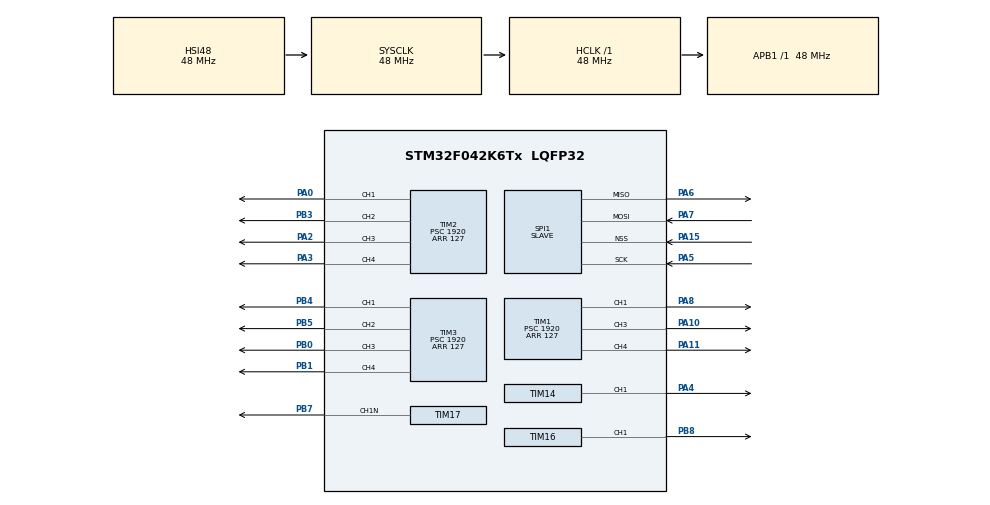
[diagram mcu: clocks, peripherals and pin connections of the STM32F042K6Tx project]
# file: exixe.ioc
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Dma.Request0=SPI1_RX
Dma.SPI1_RX.0.Direction=DMA_PERIPH_TO_MEMORY
Dma.SPI1_RX.0.Instance=DMA1_Channel2
Dma.SPI1_RX.0.MemDataAlignment=DMA_MDATAALIGN_BYTE
Dma.SPI1_RX.0.MemInc=DMA_MINC_ENABLE
Dma.SPI1_RX.0.Mode=DMA_NORMAL
Dma.SPI1_RX.0.PeriphDataAlignment=DMA_PDATAALIGN_BYTE
Dma.SPI1_RX.0.PeriphInc=DMA_PINC_DISABLE
Dma.SPI1_RX.0.Priority=DMA_PRIORITY_HIGH
IWDG.Prescaler=IWDG_PRESCALER_4
Mcu.Family=STM32F0
Mcu.Name=STM32F042K6Tx
Mcu.Package=LQFP32
NVIC.DMA1_Channel2_3_IRQn=true\:0\:0\:false\:false\:true\:true
PA0.Signal=S_TIM2_CH1_ETR
PA10.Signal=S_TIM1_CH3
PA11.Signal=S_TIM1_CH4
PA13.Mode=Serial_Wire
PA13.Signal=SYS_SWDIO
PA14.Mode=Serial_Wire
PA14.Signal=SYS_SWCLK
PA15.Mode=NSS_Signal_Hard_Input
PA15.Signal=SPI1_NSS
PA2.Signal=S_TIM2_CH3
PA3.Signal=S_TIM2_CH4
PA4.Signal=S_TIM14_CH1
PA5.Mode=Full_Duplex_Slave
PA5.Signal=SPI1_SCK
PA6.Mode=Full_Duplex_Slave
PA6.Signal=SPI1_MISO
PA7.Mode=Full_Duplex_Slave
PA7.Signal=SPI1_MOSI
PA8.Signal=S_TIM1_CH1
PB0.Signal=S_TIM3_CH3
PB1.Signal=S_TIM3_CH4
PB3.Signal=S_TIM2_CH2
PB4.Signal=S_TIM3_CH1
PB5.Signal=S_TIM3_CH2
PB7.Mode=PWM Generation1 CH1N
PB7.Signal=TIM17_CH1N
PB8.Signal=S_TIM16_CH1
ProjectManager.HeapSize=0x200
ProjectManager.StackSize=0x400
ProjectManager.TargetToolchain=MDK-ARM V5
RCC.AHBFreq_Value=48000000
RCC.APB1Freq_Value=48000000
RCC.APB1TimFreq_Value=48000000
RCC.HCLKFreq_Value=48000000
RCC.I2c1ClockSelection=RCC_I2C1CLKSOURCE_SYSCLK
RCC.SYSCLKFreq_VALUE=48000000
RCC.SYSCLKSource=RCC_SYSCLKSOURCE_HSI48
RCC.Usart1ClockSelection=RCC_USART1CLKSOURCE_SYSCLK
SH.S_TIM14_CH1.0=TIM14_CH1,PWM Generation1 CH1
SH.S_TIM16_CH1.0=TIM16_CH1,PWM Generation1 CH1
SH.S_TIM1_CH1.0=TIM1_CH1,PWM Generation1 CH1
SH.S_TIM1_CH3.0=TIM1_CH3,PWM Generation3 CH3
SH.S_TIM1_CH4.0=TIM1_CH4,PWM Generation4 CH4
SH.S_TIM2_CH1_ETR.0=TIM2_CH1,PWM Generation1 CH1
SH.S_TIM2_CH2.0=TIM2_CH2,PWM Generation2 CH2
SH.S_TIM2_CH3.0=TIM2_CH3,PWM Generation3 CH3
SH.S_TIM2_CH4.0=TIM2_CH4,PWM Generation4 CH4
SH.S_TIM3_CH1.0=TIM3_CH1,PWM Generation1 CH1
SH.S_TIM3_CH2.0=TIM3_CH2,PWM Generation2 CH2
SH.S_TIM3_CH3.0=TIM3_CH3,PWM Generation3 CH3
SH.S_TIM3_CH4.0=TIM3_CH4,PWM Generation4 CH4
SPI1.DataSize=SPI_DATASIZE_8BIT
SPI1.Direction=SPI_DIRECTION_2LINES
SPI1.Mode=SPI_MODE_SLAVE
SPI1.VirtualNSS=VM_NSSHARD
SPI1.VirtualType=VM_SLAVE
TIM1.Channel-PWM\ Generation1\ CH1=TIM_CHANNEL_1
TIM1.Channel-PWM\ Generation3\ CH3=TIM_CHANNEL_3
TIM1.Channel-PWM\ Generation4\ CH4=TIM_CHANNEL_4
TIM1.Period=127
TIM1.Prescaler=1920
TIM1.Pulse-PWM\ Generation1\ CH1=0
TIM1.Pulse-PWM\ Generation4\ CH4=0
TIM14.Channel=TIM_CHANNEL_1
TIM14.Period=127
TIM14.Prescaler=1920
TIM14.Pulse=0
TIM16.Channel=TIM_CHANNEL_1
TIM16.Period=127
TIM16.Prescaler=1920
TIM17.Channel=TIM_CHANNEL_1
TIM17.Period=127
TIM17.Prescaler=1920
TIM17.Pulse=0
TIM2.Channel-PWM\ Generation1\ CH1=TIM_CHANNEL_1
TIM2.Channel-PWM\ Generation2\ CH2=TIM_CHANNEL_2
TIM2.Channel-PWM\ Generation3\ CH3=TIM_CHANNEL_3
TIM2.Channel-PWM\ Generation4\ CH4=TIM_CHANNEL_4
TIM2.Period=127
TIM2.Prescaler=1920
TIM2.Pulse-PWM\ Generation1\ CH1=0
TIM2.Pulse-PWM\ Generation2\ CH2=0
TIM2.Pulse-PWM\ Generation3\ CH3=0
TIM2.Pulse-PWM\ Generation4\ CH4=0
TIM3.Channel-PWM\ Generation1\ CH1=TIM_CHANNEL_1
TIM3.Channel-PWM\ Generation2\ CH2=TIM_CHANNEL_2
TIM3.Channel-PWM\ Generation3\ CH3=TIM_CHANNEL_3
TIM3.Channel-PWM\ Generation4\ CH4=TIM_CHANNEL_4
TIM3.Period=127
TIM3.Prescaler=1920
TIM3.Pulse-PWM\ Generation1\ CH1=0
TIM3.Pulse-PWM\ Generation2\ CH2=0
TIM3.Pulse-PWM\ Generation3\ CH3=0
TIM3.Pulse-PWM\ Generation4\ CH4=0
VP_IWDG_VS_IWDG.Mode=IWDG_Activate
VP_TIM14_VS_ClockSourceINT.Mode=Enable_Timer
VP_TIM16_VS_ClockSourceINT.Mode=Enable_Timer
VP_TIM17_VS_ClockSourceINT.Mode=Enable_Timer
VP_TIM1_VS_ClockSourceINT.Mode=Internal
VP_TIM2_VS_ClockSourceINT.Mode=Internal
VP_TIM3_VS_ClockSourceINT.Mode=Internal
board=exixe

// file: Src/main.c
/**
  ******************************************************************************
  * File Name          : main.c
  * Description        : Main program body
  ******************************************************************************
  ** This notice applies to any and all portions of this file
  * that are not between comment pairs USER CODE BEGIN and
  * USER CODE END. Other portions of this file, whether
  * inserted by the user or by software development tools
  * are owned by their respective copyright owners.
  *
  * COPYRIGHT(c) 2017 STMicroelectronics
  *
  * Redistribution and use in source and binary forms, with or without modification,
  * are permitted provided that the following conditions are met:
  *   1. Redistributions of source code must retain the above copyright notice,
  *      this list of conditions and the following disclaimer.
  *   2. Redistributions in binary form must reproduce the above copyright notice,
  *      this list of conditions and the following disclaimer in the documentation
  *      and/or other materials provided with the distribution.
  *   3. Neither the name of STMicroelectronics nor the names of its contributors
  *      may be used to endorse or promote products derived from this software
  *      without specific prior written permission.
  *
  * THIS SOFTWARE IS PROVIDED BY THE COPYRIGHT HOLDERS AND CONTRIBUTORS "AS IS"
  * AND ANY EXPRESS OR IMPLIED WARRANTIES, INCLUDING, BUT NOT LIMITED TO, THE
  * IMPLIED WARRANTIES OF MERCHANTABILITY AND FITNESS FOR A PARTICULAR PURPOSE ARE
  * DISCLAIMED. IN NO EVENT SHALL THE COPYRIGHT HOLDER OR CONTRIBUTORS BE LIABLE
  * FOR ANY DIRECT, INDIRECT, INCIDENTAL, SPECIAL, EXEMPLARY, OR CONSEQUENTIAL
  * DAMAGES (INCLUDING, BUT NOT LIMITED TO, PROCUREMENT OF SUBSTITUTE GOODS OR
  * SERVICES; LOSS OF USE, DATA, OR PROFITS; OR BUSINESS INTERRUPTION) HOWEVER
  * CAUSED AND ON ANY THEORY OF LIABILITY, WHETHER IN CONTRACT, STRICT LIABILITY,
  * OR TORT (INCLUDING NEGLIGENCE OR OTHERWISE) ARISING IN ANY WAY OUT OF THE USE
  * OF THIS SOFTWARE, EVEN IF ADVISED OF THE POSSIBILITY OF SUCH DAMAGE.
  *
  ******************************************************************************
  */
#include "main.h"
#include "stm32f0xx_hal.h"

/* USER CODE BEGIN Includes */
#include "shared.h"
#include "helpers.h"

/* USER CODE END Includes */

IWDG_HandleTypeDef hiwdg;

SPI_HandleTypeDef hspi1;
DMA_HandleTypeDef hdma_spi1_rx;

TIM_HandleTypeDef htim1;
TIM_HandleTypeDef htim2;
TIM_HandleTypeDef htim3;
TIM_HandleTypeDef htim14;
TIM_HandleTypeDef htim16;
TIM_HandleTypeDef htim17;

/* USER CODE BEGIN PV */
/* Private variables ---------------------------------------------------------*/

/* USER CODE END PV */

void SystemClock_Config(void);
static void MX_GPIO_Init(void);
static void MX_DMA_Init(void);
static void MX_SPI1_Init(void);
static void MX_TIM14_Init(void);
static void MX_TIM3_Init(void);
static void MX_TIM16_Init(void);
static void MX_TIM1_Init(void);
static void MX_TIM2_Init(void);
static void MX_TIM17_Init(void);
static void MX_IWDG_Init(void);

void HAL_TIM_MspPostInit(TIM_HandleTypeDef *htim);

/* USER CODE BEGIN PFP */
/* Private function prototypes -----------------------------------------------*/
/* USER CODE END PFP */

int main(void)
{

  /* MCU Configuration----------------------------------------------------------*/

  /* Reset of all peripherals, Initializes the Flash interface and the Systick. */
  HAL_Init();

  /* Configure the system clock */
  SystemClock_Config();

  /* Initialize all configured peripherals */
  MX_GPIO_Init();
  MX_DMA_Init();
  MX_SPI1_Init();
  MX_TIM14_Init();
  MX_TIM3_Init();
  MX_TIM16_Init();
  MX_TIM1_Init();
  MX_TIM2_Init();
  MX_TIM17_Init();
  MX_IWDG_Init();

  /* Infinite loop */
  /* USER CODE BEGIN WHILE */
  timer_init();
  HAL_Delay(10);
  while (1)
  {
    HAL_IWDG_Refresh(&hiwdg);
    if(HAL_GPIO_ReadPin(GPIOA, GPIO_PIN_15) == GPIO_PIN_SET)
      HAL_SPI_Receive_DMA(&hspi1, spi_recv_buf, SPI_BUF_SIZE);
  /* USER CODE END WHILE */

  }

}

/** System Clock Configuration
*/
void SystemClock_Config(void)
{

  RCC_OscInitTypeDef RCC_OscInitStruct;
  RCC_ClkInitTypeDef RCC_ClkInitStruct;

    /**Initializes the CPU, AHB and APB busses clocks
    */
  RCC_OscInitStruct.OscillatorType = RCC_OSCILLATORTYPE_HSI48|RCC_OSCILLATORTYPE_LSI;
  RCC_OscInitStruct.HSI48State = RCC_HSI48_ON;
  RCC_OscInitStruct.LSIState = RCC_LSI_ON;
  RCC_OscInitStruct.PLL.PLLState = RCC_PLL_NONE;
  if (HAL_RCC_OscConfig(&RCC_OscInitStruct) != HAL_OK)
  {
    _Error_Handler(__FILE__, __LINE__);
  }

    /**Initializes the CPU, AHB and APB busses clocks
    */
  RCC_ClkInitStruct.ClockType = RCC_CLOCKTYPE_HCLK|RCC_CLOCKTYPE_SYSCLK
                              |RCC_CLOCKTYPE_PCLK1;
  RCC_ClkInitStruct.SYSCLKSource = RCC_SYSCLKSOURCE_HSI48;
  RCC_ClkInitStruct.AHBCLKDivider = RCC_SYSCLK_DIV1;
  RCC_ClkInitStruct.APB1CLKDivider = RCC_HCLK_DIV1;

  if (HAL_RCC_ClockConfig(&RCC_ClkInitStruct, FLASH_LATENCY_1) != HAL_OK)
  {
    _Error_Handler(__FILE__, __LINE__);
  }

    /**Configure the Systick interrupt time
    */
  HAL_SYSTICK_Config(HAL_RCC_GetHCLKFreq()/1000);

    /**Configure the Systick
    */
  HAL_SYSTICK_CLKSourceConfig(SYSTICK_CLKSOURCE_HCLK);

  /* SysTick_IRQn interrupt configuration */
  HAL_NVIC_SetPriority(SysTick_IRQn, 0, 0);
}

/* IWDG init function */
static void MX_IWDG_Init(void)
{

  hiwdg.Instance = IWDG;
  hiwdg.Init.Prescaler = IWDG_PRESCALER_4;
  hiwdg.Init.Window = 4095;
  hiwdg.Init.Reload = 4095;
  if (HAL_IWDG_Init(&hiwdg) != HAL_OK)
  {
    _Error_Handler(__FILE__, __LINE__);
  }

}

/* SPI1 init function */
static void MX_SPI1_Init(void)
{

  hspi1.Instance = SPI1;
  hspi1.Init.Mode = SPI_MODE_SLAVE;
  hspi1.Init.Direction = SPI_DIRECTION_2LINES;
  hspi1.Init.DataSize = SPI_DATASIZE_8BIT;
  hspi1.Init.CLKPolarity = SPI_POLARITY_LOW;
  hspi1.Init.CLKPhase = SPI_PHASE_1EDGE;
  hspi1.Init.NSS = SPI_NSS_HARD_INPUT;
  hspi1.Init.FirstBit = SPI_FIRSTBIT_MSB;
  hspi1.Init.TIMode = SPI_TIMODE_DISABLE;
  hspi1.Init.CRCCalculation = SPI_CRCCALCULATION_DISABLE;
  hspi1.Init.CRCPolynomial = 7;
  hspi1.Init.CRCLength = SPI_CRC_LENGTH_DATASIZE;
  hspi1.Init.NSSPMode = SPI_NSS_PULSE_DISABLE;
  if (HAL_SPI_Init(&hspi1) != HAL_OK)
  {
    _Error_Handler(__FILE__, __LINE__);
  }

}

/* TIM1 init function */
static void MX_TIM1_Init(void)
{

  TIM_ClockConfigTypeDef sClockSourceConfig;
  TIM_MasterConfigTypeDef sMasterConfig;
  TIM_OC_InitTypeDef sConfigOC;
  TIM_BreakDeadTimeConfigTypeDef sBreakDeadTimeConfig;

  htim1.Instance = TIM1;
  htim1.Init.Prescaler = 1920;
  htim1.Init.CounterMode = TIM_COUNTERMODE_UP;
  htim1.Init.Period = 127;
  htim1.Init.ClockDivision = TIM_CLOCKDIVISION_DIV1;
  htim1.Init.RepetitionCounter = 0;
  htim1.Init.AutoReloadPreload = TIM_AUTORELOAD_PRELOAD_DISABLE;
  if (HAL_TIM_Base_Init(&htim1) != HAL_OK)
  {
    _Error_Handler(__FILE__, __LINE__);
  }

  sClockSourceConfig.ClockSource = TIM_CLOCKSOURCE_INTERNAL;
  if (HAL_TIM_ConfigClockSource(&htim1, &sClockSourceConfig) != HAL_OK)
  {
    _Error_Handler(__FILE__, __LINE__);
  }

  if (HAL_TIM_PWM_Init(&htim1) != HAL_OK)
  {
    _Error_Handler(__FILE__, __LINE__);
  }

  sMasterConfig.MasterOutputTrigger = TIM_TRGO_RESET;
  sMasterConfig.MasterSlaveMode = TIM_MASTERSLAVEMODE_DISABLE;
  if (HAL_TIMEx_MasterConfigSynchronization(&htim1, &sMasterConfig) != HAL_OK)
  {
    _Error_Handler(__FILE__, __LINE__);
  }

  sConfigOC.OCMode = TIM_OCMODE_PWM1;
  sConfigOC.Pulse = 0;
  sConfigOC.OCPolarity = TIM_OCPOLARITY_HIGH;
  sConfigOC.OCNPolarity = TIM_OCNPOLARITY_HIGH;
  sConfigOC.OCFastMode = TIM_OCFAST_DISABLE;
  sConfigOC.OCIdleState = TIM_OCIDLESTATE_RESET;
  sConfigOC.OCNIdleState = TIM_OCNIDLESTATE_RESET;
  if (HAL_TIM_PWM_ConfigChannel(&htim1, &sConfigOC, TIM_CHANNEL_1) != HAL_OK)
  {
    _Error_Handler(__FILE__, __LINE__);
  }

  if (HAL_TIM_PWM_ConfigChannel(&htim1, &sConfigOC, TIM_CHANNEL_3) != HAL_OK)
  {
    _Error_Handler(__FILE__, __LINE__);
  }

  if (HAL_TIM_PWM_ConfigChannel(&htim1, &sConfigOC, TIM_CHANNEL_4) != HAL_OK)
  {
    _Error_Handler(__FILE__, __LINE__);
  }

  sBreakDeadTimeConfig.OffStateRunMode = TIM_OSSR_DISABLE;
  sBreakDeadTimeConfig.OffStateIDLEMode = TIM_OSSI_DISABLE;
  sBreakDeadTimeConfig.LockLevel = TIM_LOCKLEVEL_OFF;
  sBreakDeadTimeConfig.DeadTime = 0;
  sBreakDeadTimeConfig.BreakState = TIM_BREAK_DISABLE;
  sBreakDeadTimeConfig.BreakPolarity = TIM_BREAKPOLARITY_HIGH;
  sBreakDeadTimeConfig.AutomaticOutput = TIM_AUTOMATICOUTPUT_DISABLE;
  if (HAL_TIMEx_ConfigBreakDeadTime(&htim1, &sBreakDeadTimeConfig) != HAL_OK)
  {
    _Error_Handler(__FILE__, __LINE__);
  }

  HAL_TIM_MspPostInit(&htim1);

}

/* TIM2 init function */
static void MX_TIM2_Init(void)
{

  TIM_ClockConfigTypeDef sClockSourceConfig;
  TIM_MasterConfigTypeDef sMasterConfig;
  TIM_OC_InitTypeDef sConfigOC;

  htim2.Instance = TIM2;
  htim2.Init.Prescaler = 1920;
  htim2.Init.CounterMode = TIM_COUNTERMODE_UP;
  htim2.Init.Period = 127;
  htim2.Init.ClockDivision = TIM_CLOCKDIVISION_DIV1;
  htim2.Init.AutoReloadPreload = TIM_AUTORELOAD_PRELOAD_DISABLE;
  if (HAL_TIM_Base_Init(&htim2) != HAL_OK)
  {
    _Error_Handler(__FILE__, __LINE__);
  }

  sClockSourceConfig.ClockSource = TIM_CLOCKSOURCE_INTERNAL;
  if (HAL_TIM_ConfigClockSource(&htim2, &sClockSourceConfig) != HAL_OK)
  {
    _Error_Handler(__FILE__, __LINE__);
  }

  if (HAL_TIM_PWM_Init(&htim2) != HAL_OK)
  {
    _Error_Handler(__FILE__, __LINE__);
  }

  sMasterConfig.MasterOutputTrigger = TIM_TRGO_RESET;
  sMasterConfig.MasterSlaveMode = TIM_MASTERSLAVEMODE_DISABLE;
  if (HAL_TIMEx_MasterConfigSynchronization(&htim2, &sMasterConfig) != HAL_OK)
  {
    _Error_Handler(__FILE__, __LINE__);
  }

  sConfigOC.OCMode = TIM_OCMODE_PWM1;
  sConfigOC.Pulse = 0;
  sConfigOC.OCPolarity = TIM_OCPOLARITY_HIGH;
  sConfigOC.OCFastMode = TIM_OCFAST_DISABLE;
  if (HAL_TIM_PWM_ConfigChannel(&htim2, &sConfigOC, TIM_CHANNEL_1) != HAL_OK)
  {
    _Error_Handler(__FILE__, __LINE__);
  }

  if (HAL_TIM_PWM_ConfigChannel(&htim2, &sConfigOC, TIM_CHANNEL_2) != HAL_OK)
  {
    _Error_Handler(__FILE__, __LINE__);
  }

  if (HAL_TIM_PWM_ConfigChannel(&htim2, &sConfigOC, TIM_CHANNEL_3) != HAL_OK)
  {
    _Error_Handler(__FILE__, __LINE__);
  }

  if (HAL_TIM_PWM_ConfigChannel(&htim2, &sConfigOC, TIM_CHANNEL_4) != HAL_OK)
  {
    _Error_Handler(__FILE__, __LINE__);
  }

  HAL_TIM_MspPostInit(&htim2);

}

/* TIM3 init function */
static void MX_TIM3_Init(void)
{

  TIM_ClockConfigTypeDef sClockSourceConfig;
  TIM_MasterConfigTypeDef sMasterConfig;
  TIM_OC_InitTypeDef sConfigOC;

  htim3.Instance = TIM3;
  htim3.Init.Prescaler = 1920;
  htim3.Init.CounterMode = TIM_COUNTERMODE_UP;
  htim3.Init.Period = 127;
  htim3.Init.ClockDivision = TIM_CLOCKDIVISION_DIV1;
  htim3.Init.AutoReloadPreload = TIM_AUTORELOAD_PRELOAD_DISABLE;
  if (HAL_TIM_Base_Init(&htim3) != HAL_OK)
  {
    _Error_Handler(__FILE__, __LINE__);
  }

  sClockSourceConfig.ClockSource = TIM_CLOCKSOURCE_INTERNAL;
  if (HAL_TIM_ConfigClockSource(&htim3, &sClockSourceConfig) != HAL_OK)
  {
    _Error_Handler(__FILE__, __LINE__);
  }

  if (HAL_TIM_PWM_Init(&htim3) != HAL_OK)
  {
    _Error_Handler(__FILE__, __LINE__);
  }

  sMasterConfig.MasterOutputTrigger = TIM_TRGO_RESET;
  sMasterConfig.MasterSlaveMode = TIM_MASTERSLAVEMODE_DISABLE;
  if (HAL_TIMEx_MasterConfigSynchronization(&htim3, &sMasterConfig) != HAL_OK)
  {
    _Error_Handler(__FILE__, __LINE__);
  }

  sConfigOC.OCMode = TIM_OCMODE_PWM1;
  sConfigOC.Pulse = 0;
  sConfigOC.OCPolarity = TIM_OCPOLARITY_HIGH;
  sConfigOC.OCFastMode = TIM_OCFAST_DISABLE;
  if (HAL_TIM_PWM_ConfigChannel(&htim3, &sConfigOC, TIM_CHANNEL_1) != HAL_OK)
  {
    _Error_Handler(__FILE__, __LINE__);
  }

  if (HAL_TIM_PWM_ConfigChannel(&htim3, &sConfigOC, TIM_CHANNEL_2) != HAL_OK)
  {
    _Error_Handler(__FILE__, __LINE__);
  }

  if (HAL_TIM_PWM_ConfigChannel(&htim3, &sConfigOC, TIM_CHANNEL_3) != HAL_OK)
  {
    _Error_Handler(__FILE__, __LINE__);
  }

  if (HAL_TIM_PWM_ConfigChannel(&htim3, &sConfigOC, TIM_CHANNEL_4) != HAL_OK)
  {
    _Error_Handler(__FILE__, __LINE__);
  }

  HAL_TIM_MspPostInit(&htim3);

}

/* TIM14 init function */
static void MX_TIM14_Init(void)
{

  TIM_OC_InitTypeDef sConfigOC;

  htim14.Instance = TIM14;
  htim14.Init.Prescaler = 1920;
  htim14.Init.CounterMode = TIM_COUNTERMODE_UP;
  htim14.Init.Period = 127;
  htim14.Init.ClockDivision = TIM_CLOCKDIVISION_DIV1;
  htim14.Init.AutoReloadPreload = TIM_AUTORELOAD_PRELOAD_DISABLE;
  if (HAL_TIM_Base_Init(&htim14) != HAL_OK)
  {
    _Error_Handler(__FILE__, __LINE__);
  }

  if (HAL_TIM_PWM_Init(&htim14) != HAL_OK)
  {
    _Error_Handler(__FILE__, __LINE__);
  }

  sConfigOC.OCMode = TIM_OCMODE_PWM1;
  sConfigOC.Pulse = 0;
  sConfigOC.OCPolarity = TIM_OCPOLARITY_HIGH;
  sConfigOC.OCFastMode = TIM_OCFAST_DISABLE;
  if (HAL_TIM_PWM_ConfigChannel(&htim14, &sConfigOC, TIM_CHANNEL_1) != HAL_OK)
  {
    _Error_Handler(__FILE__, __LINE__);
  }

  HAL_TIM_MspPostInit(&htim14);

}

/* TIM16 init function */
static void MX_TIM16_Init(void)
{

  TIM_OC_InitTypeDef sConfigOC;
  TIM_BreakDeadTimeConfigTypeDef sBreakDeadTimeConfig;

  htim16.Instance = TIM16;
  htim16.Init.Prescaler = 1920;
  htim16.Init.CounterMode = TIM_COUNTERMODE_UP;
  htim16.Init.Period = 127;
  htim16.Init.ClockDivision = TIM_CLOCKDIVISION_DIV1;
  htim16.Init.RepetitionCounter = 0;
  htim16.Init.AutoReloadPreload = TIM_AUTORELOAD_PRELOAD_DISABLE;
  if (HAL_TIM_Base_Init(&htim16) != HAL_OK)
  {
    _Error_Handler(__FILE__, __LINE__);
  }

  if (HAL_TIM_PWM_Init(&htim16) != HAL_OK)
  {
    _Error_Handler(__FILE__, __LINE__);
  }

  sConfigOC.OCMode = TIM_OCMODE_PWM1;
  sConfigOC.Pulse = 0;
  sConfigOC.OCPolarity = TIM_OCPOLARITY_HIGH;
  sConfigOC.OCNPolarity = TIM_OCNPOLARITY_HIGH;
  sConfigOC.OCFastMode = TIM_OCFAST_DISABLE;
  sConfigOC.OCIdleState = TIM_OCIDLESTATE_RESET;
  sConfigOC.OCNIdleState = TIM_OCNIDLESTATE_RESET;
  if (HAL_TIM_PWM_ConfigChannel(&htim16, &sConfigOC, TIM_CHANNEL_1) != HAL_OK)
  {
    _Error_Handler(__FILE__, __LINE__);
  }

  sBreakDeadTimeConfig.OffStateRunMode = TIM_OSSR_DISABLE;
  sBreakDeadTimeConfig.OffStateIDLEMode = TIM_OSSI_DISABLE;
  sBreakDeadTimeConfig.LockLevel = TIM_LOCKLEVEL_OFF;
  sBreakDeadTimeConfig.DeadTime = 0;
  sBreakDeadTimeConfig.BreakState = TIM_BREAK_DISABLE;
  sBreakDeadTimeConfig.BreakPolarity = TIM_BREAKPOLARITY_HIGH;
  sBreakDeadTimeConfig.AutomaticOutput = TIM_AUTOMATICOUTPUT_DISABLE;
  if (HAL_TIMEx_ConfigBreakDeadTime(&htim16, &sBreakDeadTimeConfig) != HAL_OK)
  {
    _Error_Handler(__FILE__, __LINE__);
  }

  HAL_TIM_MspPostInit(&htim16);

}

/* TIM17 init function */
static void MX_TIM17_Init(void)
{

  TIM_OC_InitTypeDef sConfigOC;
  TIM_BreakDeadTimeConfigTypeDef sBreakDeadTimeConfig;

  htim17.Instance = TIM17;
  htim17.Init.Prescaler = 1920;
  htim17.Init.CounterMode = TIM_COUNTERMODE_UP;
  htim17.Init.Period = 127;
  htim17.Init.ClockDivision = TIM_CLOCKDIVISION_DIV1;
  htim17.Init.RepetitionCounter = 0;
  htim17.Init.AutoReloadPreload = TIM_AUTORELOAD_PRELOAD_DISABLE;
  if (HAL_TIM_Base_Init(&htim17) != HAL_OK)
  {
    _Error_Handler(__FILE__, __LINE__);
  }

  if (HAL_TIM_PWM_Init(&htim17) != HAL_OK)
  {
    _Error_Handler(__FILE__, __LINE__);
  }

  sConfigOC.OCMode = TIM_OCMODE_PWM1;
  sConfigOC.Pulse = 0;
  sConfigOC.OCPolarity = TIM_OCPOLARITY_HIGH;
  sConfigOC.OCNPolarity = TIM_OCNPOLARITY_HIGH;
  sConfigOC.OCFastMode = TIM_OCFAST_DISABLE;
  sConfigOC.OCIdleState = TIM_OCIDLESTATE_RESET;
  sConfigOC.OCNIdleState = TIM_OCNIDLESTATE_RESET;
  if (HAL_TIM_PWM_ConfigChannel(&htim17, &sConfigOC, TIM_CHANNEL_1) != HAL_OK)
  {
    _Error_Handler(__FILE__, __LINE__);
  }

  sBreakDeadTimeConfig.OffStateRunMode = TIM_OSSR_DISABLE;
  sBreakDeadTimeConfig.OffStateIDLEMode = TIM_OSSI_DISABLE;
  sBreakDeadTimeConfig.LockLevel = TIM_LOCKLEVEL_OFF;
  sBreakDeadTimeConfig.DeadTime = 0;
  sBreakDeadTimeConfig.BreakState = TIM_BREAK_DISABLE;
  sBreakDeadTimeConfig.BreakPolarity = TIM_BREAKPOLARITY_HIGH;
  sBreakDeadTimeConfig.AutomaticOutput = TIM_AUTOMATICOUTPUT_DISABLE;
  if (HAL_TIMEx_ConfigBreakDeadTime(&htim17, &sBreakDeadTimeConfig) != HAL_OK)
  {
    _Error_Handler(__FILE__, __LINE__);
  }

  HAL_TIM_MspPostInit(&htim17);

}

static void MX_DMA_Init(void)
{
  /* DMA controller clock enable */
  __HAL_RCC_DMA1_CLK_ENABLE();

  /* DMA interrupt init */
  /* DMA1_Channel2_3_IRQn interrupt configuration */
  HAL_NVIC_SetPriority(DMA1_Channel2_3_IRQn, 0, 0);
  HAL_NVIC_EnableIRQ(DMA1_Channel2_3_IRQn);

}

/** Configure pins as
        * Analog
        * Input
        * Output
        * EVENT_OUT
        * EXTI
*/
static void MX_GPIO_Init(void)
{

  /* GPIO Ports Clock Enable */
  __HAL_RCC_GPIOA_CLK_ENABLE();
  __HAL_RCC_GPIOB_CLK_ENABLE();

}

/* USER CODE BEGIN 4 */
void HAL_SPI_RxCpltCallback(SPI_HandleTypeDef *hspi)
{
  if((spi_recv_buf[0] & 0xfe) != SPI_CMD_UPDATE)
    HAL_NVIC_SystemReset();
  set_pwm(spi_recv_buf);
  HAL_SPI_Receive_DMA(&hspi1, spi_recv_buf, SPI_BUF_SIZE);
}

/* USER CODE END 4 */

void _Error_Handler(char * file, int line)
{
  while(1)
  {
  }
}

/************************ (C) COPYRIGHT STMicroelectronics *****END OF FILE****/
